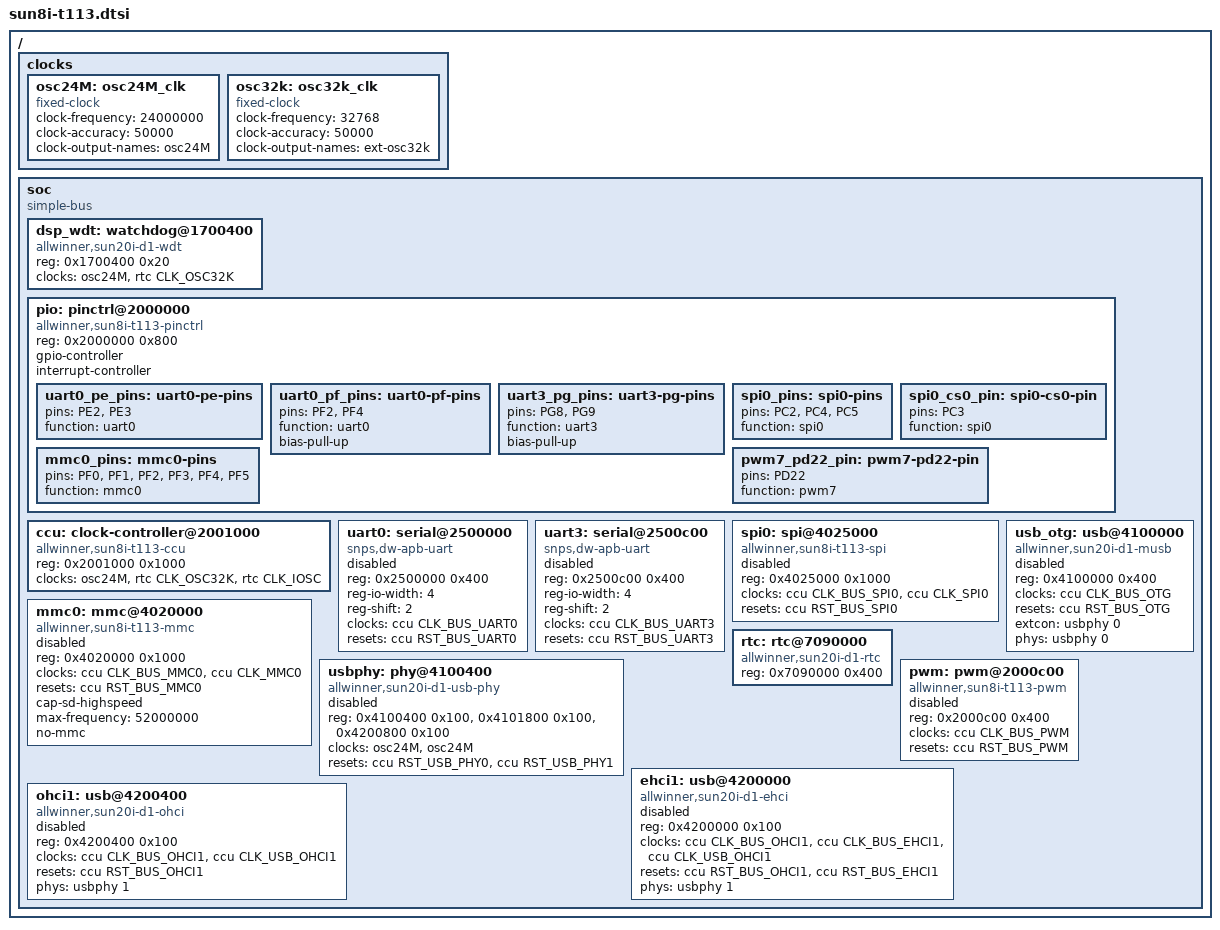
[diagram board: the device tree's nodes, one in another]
#include <dt-bindings/clock/sun8i-t113-ccu.h>
#include <dt-bindings/reset/sun8i-t113-ccu.h>
#include <dt-bindings/clock/sun6i-rtc.h>

/ {
	#address-cells = <1>;
	#size-cells = <1>;

	clocks {
		#address-cells = <1>;
		#size-cells = <1>;
		ranges;

		osc24M: osc24M_clk {
			#clock-cells = <0>;
			compatible = "fixed-clock";
			clock-frequency = <24000000>;
			clock-accuracy = <50000>;
			clock-output-names = "osc24M";
		};

		osc32k: osc32k_clk {
			#clock-cells = <0>;
			compatible = "fixed-clock";
			clock-frequency = <32768>;
			clock-accuracy = <50000>;
			clock-output-names = "ext-osc32k";
		};
	};

	soc {
		compatible = "simple-bus";
		#address-cells = <1>;
		#size-cells = <1>;
		ranges;

		dsp_wdt: watchdog@1700400 {
             compatible = "allwinner,sun20i-d1-wdt";
             reg = <0x1700400 0x20>;
             clocks = <&osc24M>, <&rtc CLK_OSC32K>;
             clock-names = "hosc", "losc";
         };

		pio: pinctrl@2000000 {
			compatible = "allwinner,sun8i-t113-pinctrl";
			reg = <0x2000000 0x800>;
			gpio-controller;
			#gpio-cells = <3>;
			interrupt-controller;
			#interrupt-cells = <3>;

			/omit-if-no-ref/
			uart0_pe_pins: uart0-pe-pins {
				pins = "PE2", "PE3";
				function = "uart0";
			};

			uart0_pf_pins: uart0-pf-pins {
				pins = "PF2", "PF4";
				function = "uart0";
				bias-pull-up;
			};

			uart3_pg_pins: uart3-pg-pins {
				pins = "PG8", "PG9";
				function = "uart3";
				bias-pull-up;
			};
			/omit-if-no-ref/
			spi0_pins: spi0-pins {
				pins = "PC2", "PC4", "PC5";
				function = "spi0";
			};

			/omit-if-no-ref/
			spi0_cs0_pin: spi0-cs0-pin {
				pins = "PC3";
				function = "spi0";
			};

			/omit-if-no-ref/
			mmc0_pins: mmc0-pins {
				pins = "PF0", "PF1", "PF2", "PF3", "PF4", "PF5";
				function = "mmc0";
			};

			/omit-if-no-ref/
			pwm7_pd22_pin: pwm7-pd22-pin {
				pins = "PD22";
				function = "pwm7";
			};
        };

		ccu: clock-controller@2001000 {
			compatible = "allwinner,sun8i-t113-ccu";
			reg = <0x2001000 0x1000>;
			clocks = <&osc24M>,
				 <&rtc CLK_OSC32K>,
				 <&rtc CLK_IOSC>;
			clock-names = "hosc", "losc", "iosc";
			#clock-cells = <1>;
			#reset-cells = <1>;
		};

		uart0: serial@2500000 {
			compatible = "snps,dw-apb-uart";
			reg = <0x2500000 0x400>;
			reg-io-width = <4>;
			reg-shift = <2>;
			clocks = <&ccu CLK_BUS_UART0>;
			resets = <&ccu RST_BUS_UART0>;
			status = "disabled";
		};

		uart3: serial@2500c00 {
			compatible = "snps,dw-apb-uart";
			reg = <0x2500c00 0x400>;
			reg-io-width = <4>;
			reg-shift = <2>;
			clocks = <&ccu CLK_BUS_UART3>;
			resets = <&ccu RST_BUS_UART3>;
			status = "disabled";
		};


		spi0: spi@4025000 {
			compatible = "allwinner,sun8i-t113-spi";
			reg = <0x4025000 0x1000>;
			// interrupts = <GIC_SPI 15 IRQ_TYPE_LEVEL_HIGH>;
			clocks = <&ccu CLK_BUS_SPI0>, <&ccu CLK_SPI0>;
			clock-names = "ahb", "mod";
			resets = <&ccu RST_BUS_SPI0>;
			// dmas = <&dma 22>, <&dma 22>;
			// dma-names = "rx", "tx";
			// num-cs = <1>;
			status = "disabled";
			#address-cells = <1>;
			#size-cells = <0>;
		};

		mmc0: mmc@4020000 {
			compatible = "allwinner,sun8i-t113-mmc";
			reg = <0x4020000 0x1000>;
			// interrupts = <GIC_SPI 40 IRQ_TYPE_LEVEL_HIGH>;
			clocks = <&ccu CLK_BUS_MMC0>, <&ccu CLK_MMC0>;
			clock-names = "ahb", "mmc";
			resets = <&ccu RST_BUS_MMC0>;
			reset-names = "ahb";
			cap-sd-highspeed;
			max-frequency = <52000000>;
			no-mmc;
			status = "disabled";
			#address-cells = <1>;
			#size-cells = <0>;
		};

		usb_otg: usb@4100000 {
			compatible = "allwinner,sun20i-d1-musb",
				     "allwinner,sun8i-a33-musb";
			reg = <0x4100000 0x400>;
			// interrupts = <GIC_SPI 29 IRQ_TYPE_LEVEL_HIGH>;
			interrupt-names = "mc";
			clocks = <&ccu CLK_BUS_OTG>;
			resets = <&ccu RST_BUS_OTG>;
			extcon = <&usbphy 0>;
			phys = <&usbphy 0>;
			phy-names = "usb";
			status = "disabled";
		};

		usbphy: phy@4100400 {
			compatible = "allwinner,sun20i-d1-usb-phy";
			reg = <0x4100400 0x100>,
			      <0x4101800 0x100>,
			      <0x4200800 0x100>;
			reg-names = "phy_ctrl",
				    "pmu0",
				    "pmu1";
			clocks = <&osc24M>,
				 <&osc24M>;
			clock-names = "usb0_phy",
				      "usb1_phy";
			resets = <&ccu RST_USB_PHY0>,
				 <&ccu RST_USB_PHY1>;
			reset-names = "usb0_reset",
				      "usb1_reset";
			status = "disabled";
			#phy-cells = <1>;
		};

		rtc: rtc@7090000 {
			compatible = "allwinner,sun20i-d1-rtc",
				     "allwinner,sun50i-r329-rtc";
			reg = <0x7090000 0x400>;
			// interrupts = <GIC_SPI 144 IRQ_TYPE_LEVEL_HIGH>;
			// clocks = <&r_ccu CLK_BUS_R_RTC>,
			// 	 <&osc24M>,
			// 	 <&r_ccu CLK_R_AHB>;
			clock-names = "bus", "hosc", "ahb";
			#clock-cells = <1>;
		};

		pwm: pwm@2000c00 {
			compatible = "allwinner,sun8i-t113-pwm";
			reg = <0x2000c00 0x400>;
            clocks = <&ccu CLK_BUS_PWM>;
            resets = <&ccu RST_BUS_PWM>;
            #pwm-cells = <3>;
            status = "disabled";
        };  

		ehci1: usb@4200000 {
			compatible = "allwinner,sun20i-d1-ehci",
				     "generic-ehci";
			reg = <0x4200000 0x100>;
			// interrupts = <GIC_SPI 33 IRQ_TYPE_LEVEL_HIGH>;
			clocks = <&ccu CLK_BUS_OHCI1>,
				 <&ccu CLK_BUS_EHCI1>,
				 <&ccu CLK_USB_OHCI1>;
			resets = <&ccu RST_BUS_OHCI1>,
				 <&ccu RST_BUS_EHCI1>;
			phys = <&usbphy 1>;
			phy-names = "usb";
			status = "disabled";
		};

		ohci1: usb@4200400 {
			compatible = "allwinner,sun20i-d1-ohci",
				     "generic-ohci";
			reg = <0x4200400 0x100>;
			// interrupts = <GIC_SPI 34 IRQ_TYPE_LEVEL_HIGH>;
			clocks = <&ccu CLK_BUS_OHCI1>,
				 <&ccu CLK_USB_OHCI1>;
			resets = <&ccu RST_BUS_OHCI1>;
			phys = <&usbphy 1>;
			phy-names = "usb";
			status = "disabled";
		};      
	};
};



